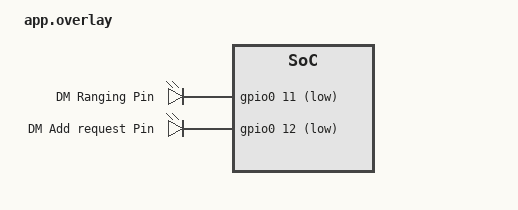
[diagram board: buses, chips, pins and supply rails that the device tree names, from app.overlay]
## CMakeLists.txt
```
#
# Copyright (c) 2021 Nordic Semiconductor
#
# SPDX-License-Identifier: LicenseRef-Nordic-5-Clause
#
cmake_minimum_required(VERSION 3.20)

find_package(Zephyr REQUIRED HINTS $ENV{ZEPHYR_BASE})
project(nrf_dm)

include_directories(src/inc)

# NORDIC SDK APP START
target_sources(app PRIVATE
  src/main.c
  src/advertise.c
  src/color.c
  )
# NORDIC SDK APP END

zephyr_library_include_directories(${CMAKE_CURRENT_SOURCE_DIR})
```

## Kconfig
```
config MCPD_DISTANCE
    bool "MCPD Distance"
config RTT_DISTANCE
    bool "RTT Distance"

config INDICATOR_LED_SATURATION
    int "Indicator LED saturation in hundredths"
    default 90
config INDICATOR_LED_LUMINANCE
    int "Indicator LED luminance in hundredths"
    default 40


source "Kconfig.zephyr"
```

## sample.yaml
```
sample:
  description: nRF Distance Measurement sample
  name: Distance measurement sample
tests:
  sample.bluetooth.nrf_dm.timeslot:
    build_only: true
    extra_configs:
      - CONFIG_DM_HIGH_PRECISION_CALC=n
    integration_platforms:
      - nrf52dk_nrf52832
      - nrf52833dk_nrf52833
      - nrf52840dk_nrf52840
      - nrf5340dk_nrf5340_cpuapp
      - thingy53_nrf5340_cpuapp
    platform_allow: >
      nrf52dk_nrf52832 nrf52833dk_nrf52833 nrf52840dk_nrf52840 nrf5340dk_nrf5340_cpuapp thingy53_nrf5340_cpuapp
    tags: bluetooth ci_build
  sample.bluetooth.nrf_dm.timeslot.high_precision:
    build_only: true
    extra_configs:
      - CONFIG_DM_HIGH_PRECISION_CALC=y
    integration_platforms:
      - nrf52833dk_nrf52833
      - nrf52840dk_nrf52840
      - nrf5340dk_nrf5340_cpuapp
      - thingy53_nrf5340_cpuapp
    platform_allow: nrf52833dk_nrf52833 nrf52840dk_nrf52840 nrf5340dk_nrf5340_cpuapp thingy53_nrf5340_cpuapp
    tags: bluetooth ci_build
```

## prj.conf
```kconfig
#
# Copyright (c) 2021 Nordic Semiconductor ASA
#
# SPDX-License-Identifier: LicenseRef-Nordic-5-Clause
#

# BT
CONFIG_BT=y
CONFIG_BT_DEBUG_LOG=y

CONFIG_BT_CENTRAL=y
CONFIG_BT_PERIPHERAL=y

CONFIG_BT_SCAN=y
CONFIG_BT_SCAN_FILTER_ENABLE=y
CONFIG_BT_SCAN_NAME_CNT=1
CONFIG_BT_SCAN_MANUFACTURER_DATA_CNT=1
CONFIG_BT_SCAN_WITH_IDENTITY=y

CONFIG_BT_EXT_ADV=y

CONFIG_BT_DEVICE_NAME="nRF_DM"

# Distance Measurement
CONFIG_DM_MODULE=y

CONFIG_MPSL=y
CONFIG_MPSL_TIMESLOT_SESSION_COUNT=1

CONFIG_DM_MODULE_LOG_LEVEL_DBG=y
CONFIG_DM_GPIO_DEBUG=y

CONFIG_DM_HIGH_PRECISION_CALC=y

CONFIG_LOG=y

CONFIG_PM_DEVICE=y

CONFIG_PWM=y

CONFIG_ENTROPY_GENERATOR=y

CONFIG_SYS_HASH_FUNC32=y
CONFIG_SYS_HASH_FUNC32_MURMUR3=y

CONFIG_MCPD_DISTANCE=y
CONFIG_LOG_MODE_DEFERRED=y

CONFIG_BT_FILTER_ACCEPT_LIST=y
```

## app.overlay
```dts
/*
 * Copyright (c) 2023 Nordic Semiconductor ASA
 *
 * SPDX-License-Identifier: LicenseRef-Nordic-5-Clause
 */

/ {
	/* The timer instance to use. */
	chosen {
		ncs,dm-timer = &timer2;
	};

	/* The selected pins will be used by Distance Measurement module for debug purposes. */
	dm_gpio {
		compatible = "gpio-leds";
		dm_ranging: dm-ranging {
			gpios = <&gpio0 11 GPIO_ACTIVE_LOW>;
			label = "DM Ranging Pin";
		};
		dm_add_request: dm-add-request {
			gpios = <&gpio0 12 GPIO_ACTIVE_LOW>;
			label = "DM Add request Pin";
		};
	};
};
```

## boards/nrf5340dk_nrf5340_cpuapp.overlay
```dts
/*
 * Copyright (c) 2022 Nordic Semiconductor ASA
 *
 * SPDX-License-Identifier: LicenseRef-Nordic-5-Clause
 */

#include <zephyr/dt-bindings/ipc_service/static_vrings.h>

/ {
	chosen {
		/delete-property/ zephyr,ipc_shm;
	};

	reserved-memory {
		/delete-node/ memory@20070000;

		sram_ipc0: memory@20070000 {
			reg = <0x20070000 0x8000>;
		};

		sram_ipc1: memory@20078000 {
			reg = <0x20078000 0x8000>;
		};
	};

	ipc {
		/delete-node/ ipc0;

		ipc0: ipc0 {
			compatible = "zephyr,ipc-openamp-static-vrings";
			memory-region = <&sram_ipc0>;
			mboxes = <&mbox 0>, <&mbox 1>;
			mbox-names = "tx", "rx";
			role = "host";
			status = "okay";
		};

		ipc1: ipc1 {
			compatible = "zephyr,ipc-openamp-static-vrings";
			memory-region = <&sram_ipc1>;
			mboxes = <&mbox 2>, <&mbox 3>;
			mbox-names = "tx", "rx";
			role = "host";
			zephyr,buffer-size = <2048>;
			status = "okay";
		};
	};
};

 /* Enable pin forwarding to network core. The selected pins will be used by
  * Distance Measurement module for debug purposes.
  *
  * Note: Pay attention to assign the same GPIO pins as those provide in network core DTS overlay.
  */
&gpio_fwd {
	compatible = "nordic,nrf-gpio-forwarder";
	dm-gpio-if {
		gpios = <&gpio0 26 0>,
			<&gpio0 27 0>;
		};
};

&adc {
	status = "disabled";
};

&i2c1 {
	status = "disabled";
};

&nfct {
	status = "disabled";
};

&qspi {
	status = "disabled";
};

&spi4 {
	status = "disabled";
};

&uart0 {
	status = "disabled";
};

&usbd {
	status = "disabled";
};
```

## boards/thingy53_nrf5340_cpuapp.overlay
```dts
/*
 * Copyright (c) 2023 Nordic Semiconductor ASA
 *
 * SPDX-License-Identifier: LicenseRef-Nordic-5-Clause
 */

 #include <zephyr/dt-bindings/ipc_service/static_vrings.h>

 / {
     chosen {
         /delete-property/ zephyr,ipc_shm;
     };
 
     reserved-memory {
         /delete-node/ memory@20070000;
 
         sram_ipc0: memory@20070000 {
             reg = <0x20070000 0x8000>;
         };
 
         sram_ipc1: memory@20078000 {
             reg = <0x20078000 0x8000>;
         };
     };
 
     ipc {
         /delete-node/ ipc0;
 
         ipc0: ipc0 {
             compatible = "zephyr,ipc-openamp-static-vrings";
             memory-region = <&sram_ipc0>;
             mboxes = <&mbox 0>, <&mbox 1>;
             mbox-names = "tx", "rx";
             role = "host";
             status = "okay";
         };
 
         ipc1: ipc1 {
             compatible = "zephyr,ipc-openamp-static-vrings";
             memory-region = <&sram_ipc1>;
             mboxes = <&mbox 2>, <&mbox 3>;
             mbox-names = "tx", "rx";
             role = "host";
             zephyr,buffer-size = <2048>;
             status = "okay";
         };
     };
 };
 
  /* Enable pin forwarding to network core. The selected pins will be used by
   * Distance Measurement module for debug purposes.
   *
   * Note: Pay attention to assign the same GPIO pins as those provide in network core DTS overlay.
   */
 &gpio_fwd {
     compatible = "nordic,nrf-gpio-forwarder";
     dm-gpio-if {
         gpios = <&gpio0 11 0>,
             <&gpio0 12 0>;
         };
 };
```

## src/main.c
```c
#include <zephyr/kernel.h>
#include <zephyr/logging/log.h>
#include <zephyr/drivers/pwm.h>
#include <zephyr/sys/hash_function.h>

#include <zephyr/bluetooth/bluetooth.h>

#include <dm.h>

#include <advertise.h>
#include <color.h>

LOG_MODULE_REGISTER(main, LOG_LEVEL_DBG);

#ifdef CONFIG_BOARD_THINGY53_NRF5340_CPUAPP
static const struct pwm_dt_spec red_pwm_led =
	PWM_DT_SPEC_GET(DT_ALIAS(pwm_led0));
static const struct pwm_dt_spec green_pwm_led =
	PWM_DT_SPEC_GET(DT_ALIAS(pwm_led1));
static const struct pwm_dt_spec blue_pwm_led =
	PWM_DT_SPEC_GET(DT_ALIAS(pwm_led2));

#define PWM_PERIOD_USEC 2000

void set_led_color(uint32_t rgba_color) {
	uint8_t red = (rgba_color >> 24) & 0xFF;
	uint8_t green = (rgba_color >> 16) & 0xFF;
	uint8_t blue = (rgba_color >> 8) & 0xFF;
	uint8_t alpha = rgba_color & 0xFF;

	uint32_t red_duty = PWM_USEC((PWM_PERIOD_USEC * red * alpha) / (0xFF * 0xFF));
	uint32_t green_duty = PWM_USEC((PWM_PERIOD_USEC * green * alpha) / (0xFF * 0xFF));
	uint32_t blue_duty = PWM_USEC((PWM_PERIOD_USEC * blue * alpha) / (0xFF * 0xFF));

	uint32_t period = PWM_USEC(PWM_PERIOD_USEC);

	pwm_set_dt(&red_pwm_led, period, red_duty);	
	pwm_set_dt(&green_pwm_led, period, green_duty);
	pwm_set_dt(&blue_pwm_led, period, blue_duty);
}

#endif

bool ranged = false;

void data_ready(struct dm_result *result)
{
	if (!result) {
		return;
	}
	ranged = true;

	const char *quality[DM_QUALITY_NONE + 1] = {"ok", "poor", "do not use", "crc fail", "none"};
	char addr[BT_ADDR_LE_STR_LEN];

	bt_addr_le_to_str(&result->bt_addr, addr, sizeof(addr));
	// Convert bt_addr to uint64_t

	LOG_INF("Measurement result:\n");
	LOG_INF("Addr: %s\n", addr);
	LOG_INF("Quality: %s\n", quality[result->quality]);

	LOG_INF("Distance estimates: ");
	LOG_INF("mcpd: ifft=%.2f phase_slope=%.2f rssi_openspace=%.2f best=%.2f\n",
		result->dist_estimates.mcpd.ifft,
		result->dist_estimates.mcpd.phase_slope,
		result->dist_estimates.mcpd.rssi_openspace,
		result->dist_estimates.mcpd.best);
	// Convert the "best" estimate to a color between 0-255
}


static struct dm_cb dm_cb = {
	.data_ready = data_ready,
};

int main(void)
{
	int err;

	struct dm_init_param init_param;
	init_param.cb = &dm_cb;

#ifdef CONFIG_BOARD_THINGY53_NRF5340_CPUAPP
	if (!device_is_ready(red_pwm_led.dev)) {
		LOG_ERR("Red LED PWM device not ready\n");
	}

	if (!device_is_ready(green_pwm_led.dev)) {
		LOG_ERR("Green LED PWM device not ready\n");
	}

	if (!device_is_ready(blue_pwm_led.dev)) {
		LOG_ERR("Blue LED PWM device not ready\n");
	}
#endif

	err = bt_enable(NULL);
	if (err) {
		LOG_ERR("Bluetooth failed to start (err %d)\n", err);
	}
	LOG_INF("Bluetooth initialized\n");

	err = advertise_init();
	if (err) {
		LOG_ERR("Advertising failed to start (err %d)\n", err);
	}
	LOG_INF("Advertising initialized\n");

	err = dm_init(&init_param);
	if (err) {
		LOG_ERR("Distance measurement failed to start (err %d)\n", err);
	}
	LOG_INF("Distance measurement initialized\n");
#ifdef CONFIG_BOARD_THINGY53_NRF5340_CPUAPP
	uint32_t color = 0x0000FFFF;
	while (!ranged) {
		// Make the LED fade up and down over time
		for (int i = 0; i < 255; i++) {
			color = (color & 0xFFFFFF00) | i;
			set_led_color(color);
			k_msleep(10);
		}
		for (int i = 255; i > 0; i--) {
			color = (color & 0xFFFFFF00) | i;
			set_led_color(color);
			k_msleep(10);
		}
	}
	set_led_color(hash_to_color());
#endif

	while(true) {
		k_sleep(K_FOREVER);
	}
}
```

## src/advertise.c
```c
#include "advertise.h"

#include <zephyr/kernel.h>
#include <zephyr/logging/log.h>

#include <zephyr/bluetooth/bluetooth.h>
#include <zephyr/bluetooth/hci.h>
#include <zephyr/bluetooth/conn.h>
#include <zephyr/bluetooth/uuid.h>
#include <zephyr/bluetooth/gatt.h>
#include <bluetooth/gatt_dm.h>

#include <zephyr/random/random.h>

#include <dm.h>

LOG_MODULE_REGISTER(advertise, LOG_LEVEL_DBG);

#define DEVICE_NAME             "Thingy" 
#define DEVICE_NAME_LEN         (sizeof(DEVICE_NAME) - 1)

#define COMPANY_CODE 0x0059
#define SUPPORT_MCPD_CODE 0x0D17A9CE
#define SUPPORT_RTT_CODE 0x1D17A9CE

static struct bt_le_ext_adv *adv;

struct adv_mfg_data {
	uint16_t company_code;	    /* Company Identifier Code. */
	uint32_t support_dm_code;   /* To identify the device that supports distance measurement. */
	uint32_t rng_seed;          /* Random seed used for generating hopping patterns. */
} __packed;

static struct adv_mfg_data mfg_data;

struct bt_le_adv_param adv_param_noconn =
	BT_LE_ADV_PARAM_INIT(BT_LE_ADV_OPT_USE_IDENTITY |
				BT_LE_ADV_OPT_SCANNABLE |
				BT_LE_ADV_OPT_NOTIFY_SCAN_REQ |
				BT_LE_ADV_OPT_CONNECTABLE,
				BT_GAP_ADV_FAST_INT_MIN_2,
				BT_GAP_ADV_FAST_INT_MAX_2,
				NULL);


struct bt_le_adv_param *adv_param = &adv_param_noconn;

static const struct bt_data ad[] = {
	BT_DATA_BYTES(BT_DATA_FLAGS, (BT_LE_AD_GENERAL | BT_LE_AD_NO_BREDR)),
	BT_DATA(BT_DATA_MANUFACTURER_DATA, (unsigned char *)&mfg_data, sizeof(mfg_data)),
	BT_DATA(BT_DATA_NAME_COMPLETE, DEVICE_NAME, DEVICE_NAME_LEN),
};

#define BT_UUID_NULL BT_UUID_128_ENCODE(0, 0, 0, 0, 0)

static struct bt_data sd[] = {
	BT_DATA(BT_DATA_MANUFACTURER_DATA, (unsigned char *)&mfg_data, sizeof(mfg_data)),
	BT_DATA_BYTES(BT_DATA_UUID128_ALL, BT_UUID_NULL),
};


static void adv_scanned_cb(struct bt_le_ext_adv *adv, struct bt_le_ext_adv_scanned_info *info) {
    struct dm_request req;

    bt_addr_le_copy(&req.bt_addr, info->addr);
    req.role = DM_ROLE_REFLECTOR;
	#ifdef CONFIG_MCPD_DISTANCE
    req.ranging_mode = DM_RANGING_MODE_MCPD;
	#endif

	#ifdef CONFIG_RTT_DISTANCE
	req.ranging_mode = DM_RANGING_MODE_RTT;
	#endif

    /* We need to make sure that we only initiate a ranging to a single peer.
        * A scan response from this device can be received by multiple peers which can
        * all start a ranging at the same time as a consequence. To prevent this,
        * we need to make sure that we set a per-peer random as the random seed.
        * This helps the ranging library to avoid interference from other devices
        * trying to range at the same time.
        *
        * This means that the initiator and the reflector need to set the same value
        * for the random seed.
        */
    bt_addr_le_copy(&req.bt_addr, info->addr);
    req.rng_seed = mfg_data.rng_seed;
    req.start_delay_us = 0;
    req.extra_window_time_us = 0;

    dm_request_add(&req);
}

static void connected(struct bt_conn *conn, uint8_t err) {
	char addr[BT_ADDR_LE_STR_LEN];

	if (err) {
		LOG_ERR("Connection failed (err %u)\n", err);
		return;
	}

	bt_addr_le_to_str(bt_conn_get_dst(conn), addr, sizeof(addr));
	LOG_INF("Connected %s\n", addr);
}

static void disconnected(struct bt_conn *conn, uint8_t reason) {
	LOG_INF("Disconnected (reason %u)", reason);
}

BT_CONN_CB_DEFINE(conn_callbacks) = {
	.connected = connected,
	.disconnected = disconnected, };
const static struct bt_le_ext_adv_cb adv_cb = {
	.scanned = adv_scanned_cb
};


int advertise_init(void) {
    int err;

	int uuid[16] = {0};
	sys_csrand_get(uuid, 16);

	sd[1].data = uuid;
	sd[1].data_len = 16;
	sd[1].type = BT_DATA_UUID128_ALL;

    mfg_data.company_code = COMPANY_CODE;
	#ifdef CONFIG_MCPD_DISTANCE
    mfg_data.support_dm_code = SUPPORT_MCPD_CODE;
	#endif

	#ifdef CONFIG_RTT_DISTANCE
	mfg_data.support_dm_code = SUPPORT_RTT_CODE;
	#endif

	sys_csrand_get(&mfg_data.rng_seed, sizeof(mfg_data.rng_seed));

    struct bt_le_ext_adv_start_param ext_adv_start_param = {0};

    if (adv) {
		err = bt_le_ext_adv_stop(adv);
		if (err) {
			LOG_ERR("Failed to stop extended advertising  (err %d)\n", err);
			return err;
		}
			err = bt_le_ext_adv_delete(adv);
		if (err) {
			LOG_ERR("Failed to delete advertising set  (err %d)\n", err);
			return err;
		}
	}

	err = bt_le_ext_adv_create(adv_param, &adv_cb, &adv);
	if (err) {
		LOG_ERR("Failed to create advertising set (err %d)\n", err);
		return err;
	}

	err = bt_le_ext_adv_set_data(adv, ad, ARRAY_SIZE(ad), sd, ARRAY_SIZE(sd));
	if (err) {
		LOG_ERR("Failed setting adv data (err %d)\n", err);
		return err;
	}

	err = bt_le_filter_accept_list_clear();
	if (err) {
		LOG_ERR("Failed to clear accept list (err %d)\n", err);
	}

	err = bt_le_ext_adv_start(adv, &ext_adv_start_param);
	if (err) {
		LOG_ERR("Failed to start extended advertising  (err %d)\n", err);
		return err;
	}

	return err;
}
```

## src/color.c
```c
#include <math.h>
#include <stdint.h>
#include <zephyr/logging/log.h>
#include <zephyr/bluetooth/bluetooth.h>
#include <zephyr/sys/hash_function.h>

LOG_MODULE_REGISTER(color, LOG_LEVEL_DBG);

static float hue_to_rgb(float temp1, float temp2, float hue) {
	if (hue < 0) hue += 1;
	if (hue > 1) hue -= 1;
	if (hue < 1.0 / 6.0) return temp1 + (temp2 - temp1) * 6 * hue;
	if (hue < 0.5) return temp2;
	if (hue < 2.0 / 3.0) return temp1 + (temp2 - temp1) * (2.0 / 3.0 - hue) * 6;
	return temp1;
}

static uint32_t hsl_to_rgba(float h, float s, float l) {
    float r, g, b;
    float temp1, temp2;

    if (s == 0) {
        r = g = b = l;
    } else {
        temp2 = (l < 0.5) ? (l * (1 + s)) : ((l + s) - (s * l));
        temp1 = 2 * l - temp2;


        r = hue_to_rgb(temp1, temp2, h / 360.0 + 1.0 / 3.0);
        g = hue_to_rgb(temp1, temp2, h / 360.0);
        b = hue_to_rgb(temp1, temp2, h / 360.0 - 1.0 / 3.0);
    }

    uint32_t rgba = ((uint32_t)(r * 255) << 24) | ((uint32_t)(g * 255) << 16) | ((uint32_t)(b * 255) << 8) | 0xFF;
    return rgba;
}

uint32_t hash_to_color(void) {
	// Get my address and convert to color:
	const char addr_local_str[BT_ADDR_LE_STR_LEN];
	bt_addr_le_t addr_local = {0};
	size_t count = 1;

	bt_id_get(&addr_local, &count);
	bt_addr_le_to_str(&addr_local, addr_local_str, sizeof(addr_local_str));

	uint32_t color_hash = sys_hash32_murmur3(addr_local_str, 17);

    float hue = (color_hash % 360) * 1.0;
    float saturation = CONFIG_INDICATOR_LED_SATURATION/100.0;
    float luminance = CONFIG_INDICATOR_LED_LUMINANCE/100.0;
    uint32_t rgba = hsl_to_rgba(hue, saturation, luminance);
    LOG_INF("Color: %x", rgba);
    LOG_INF("Hue: %f Saturation: %f Luminance: %f", hue, saturation, luminance);
    return rgba;
}
```
